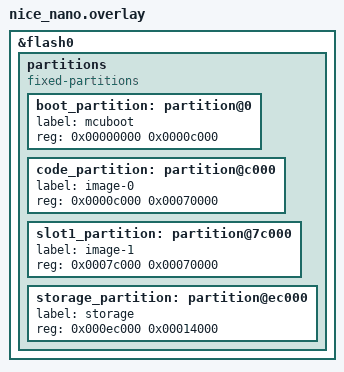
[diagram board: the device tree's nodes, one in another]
&flash0 {
        partitions {
                compatible = "fixed-partitions";
                #address-cells = <1>;
                #size-cells = <1>;

                boot_partition: partition@0 {
                        label = "mcuboot";
                        reg = <0x00000000 0x0000c000>;
                };
                code_partition: partition@c000 {
                        label = "image-0";
                        reg = <0x0000c000 0x00070000>;
                };
                slot1_partition: partition@7c000 {
                        label = "image-1";
                        reg = <0x0007c000 0x00070000>;
                };
                storage_partition: partition@ec000 {
                        label = "storage";
                        reg = <0x000ec000 0x00014000>;
                };
        };
};
